# TLE986x register map
File version: 2.5
Registers are 32-bit, read-write, reset 0x0 unless marked. A register's access mark holds for its fields unless they carry their own. Offsets are from the block's base; [hi:lo] are bit positions; {n}, {i} and the like mark numbered series; 'fields as' and 'values as' point back to an identical list.

## ADC2
Base 0x4801C000
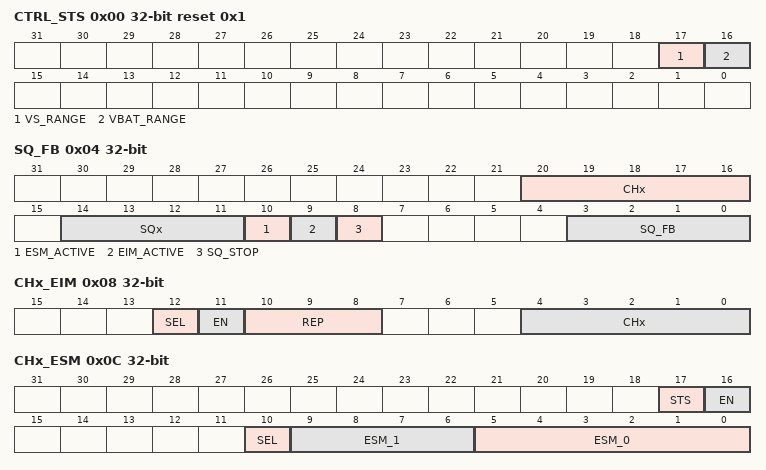
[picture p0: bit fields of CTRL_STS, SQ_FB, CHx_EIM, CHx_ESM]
0x00 CTRL_STS reset 0x1 — ADC2 Control and Status Register
  [17] VS_RANGE — ADC2 Channel 1 Range Selection
    0=Range 1 (Range from 3 to 22 V is selected); 1=Range 2 (Range from 3 to 28 V is selected)
  [16] VBAT_RANGE — ADC2 Channel 0 Range Selection
    values as VS_RANGE
0x04 SQ_FB ro (reset mask 0xFFE080F0) — Sequencer Feedback Register
  [20:16] CHx — Current ADC2 Channel
    {v}=CH{v} (Channel {v} enable) (v=0..6); 29=CH7 (Channel 7 enable); 30=CH8 (Channel 8 enable); 31=CH9 (Channel 9 enable)
  [14:11] SQx — Current Active Sequencer
    {v}=SQ{v} (Sequence {v} enable) (v=0..9)
  [10] ESM_ACTIVE — ADC2 ESM active
    0=not active (ESM not active); 1=active (ESM active)
  [9] EIM_ACTIVE — ADC2 EIM active
    0=not active (EIM not active); 1=active (EIM active)
  [8] SQ_STOP — ADC2 Sequencer Stop Signal for DPP
    0=DPP Running (Postprocessing Sequencer in running mode); 1=DPP Stopped (Postprocessing Sequencer stopped / Software Mode entered)
  [3:0] SQ_FB — Current Sequence that caused software mode
    {v}=SQ{v+1} (Sequence {v+1}) (v=0..9); 10=ESM; 11=CH_MASK (Channel Mask = 0); 12=SUSPEND (Debug Suspend Mode)
0x08 CHx_EIM — Channel Settings Bits for Exceptional Interrupt Measurement
  [12] SEL — Exceptional interrupt measurement (EIM) Trigger Trigger select
    0=CCU6_SEL (ccu6_int triggers EIM); 1=CP_SEL (cp_clk triggers EIM)
  [11] EN — Exceptional interrupt measurement (EIM) Trigger Event enable
    0=DISABLE (start of EIM disabled); 1=ENABLE (start of IEM enabled)
  [10:8] REP — Repeat count for exceptional interrupt measurement (EIM)
    {v}=Measurements (v=0..7)
  [4:0] CHx — Channel set for exceptional interrupt measurement (EIM)
    {v}=CH{v}_EN (Channel {v} enable) (v=0..6); 29=CH7_EN (Channel 7 enable); 30=CH8_EN (Channel 8 enable); 31=CH9_EN (Channel 9 enable)
0x0C CHx_ESM access per field — Channel Settings Bits for Exceptional Sequence Measurement
  [17] STS ro — Exceptional Sequence Measurement is finished
    0=not active (Exceptional Sequence Measurement not done); 1=done (Exceptional Sequence Measurement done)
  [16] EN rw — Enable for Exceptional Sequence Measurement Trigger Event
    0=Disable (start of ESM disabled); 1=Enable (start of ESM enabled)
  [10] SEL rw — Exceptional Sequence Measurement Trigger Select
    0=CCU6_SEL (ccu6_int starts ESM); 1=CP_SEL (cp_clk starts ESM)
  [9:6] ESM_1 rw — Channel Sequence for Exceptional Sequence Measurement (ESM)
    1=CH6_EN (Channel 6 enable); 2=CH7_EN (Channel 7 enable); 4=CH8_EN (Channel 8 enable); 8=CH9_EN (Channel 9 enable)
  [5:0] ESM_0 rw — Channel Sequence for Exceptional Sequence Measurement (ESM)
    1=CH0_EN (Channel 0 enable); 2=CH1_EN (Channel 1 enable); 4=CH2_EN (Channel 2 enable); 8=CH3_EN (Channel 3 enable); 16=CH4_EN (Channel 4 enable); 32=CH5_EN (Channel 5 enable)
0x14 CTRL1 — Measurement Unit Control Register 1
  [5:0] CALIB_EN — Calibration Enable for Channels 0 to 5
    1=CH0_EN (Channel 0 calibration enable); 2=CH1_EN (Channel 1 calibration enable); 4=CH2_EN (Channel 2 calibration enable); 8=CH3_EN (Channel 3 calibration enable); 16=CH4_EN (Channel 4 calibration enable); 32=CH5_EN (Channel 5 calibration enable)
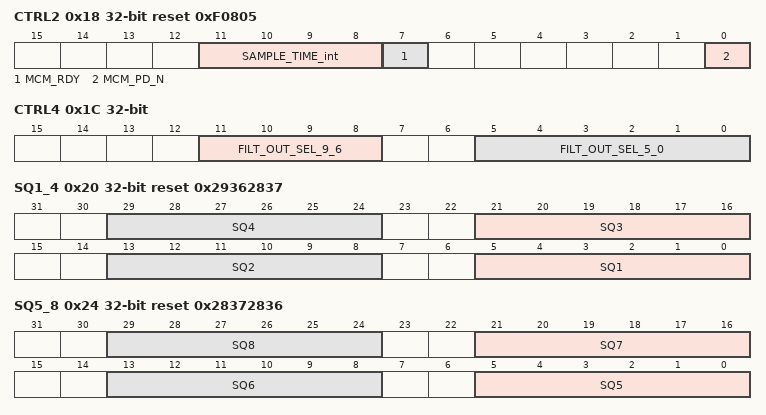
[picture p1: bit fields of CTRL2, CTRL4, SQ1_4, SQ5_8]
0x18 CTRL2 access per field reset 0xF0805 — Measurement Unit Control Register 2
  [11:8] SAMPLE_TIME_int rw — Sample time of ADC2
    0=MICLK4 (4 MI_CLK clock periods); 1=MICLK6 (6 MI_CLK clock periods); 2=MICLK8 (8 MI_CLK clock periods); 3=MICLK10 (10 MI_CLK clock periods); 4=MICLK12 (12 MI_CLK clock periods (default)); 5=MICLK14 (14 MI_CLK clock periods); 6=MICLK16 (16 MI_CLK clock periods); 7=MICLK18 (18 MI_CLK clock periods); 8=MICLK20 (20 MI_CLK clock periods); 9=MICLK22 (22 MI_CLK clock periods); {v}=n.u. (not used) (v=10..15)
  [7] MCM_RDY ro — Ready Signal for MCM after Power On or Reset
    0=MCM Not Ready (Measurement Core Module in startup phase); 1=MCM Ready (Measurement Core Module start-up phase finished)
  [0] MCM_PD_N rw — Power Down Signal for MCM
    0=MCM Disabled (Measurement Core Module Disabled); 1=MCM Enabled (Measurement Core Module Enabled)
0x1C CTRL4 — Measurement Unit Control Register 4
  [11:8] FILT_OUT_SEL_9_6 — Output Filter Selection for Channels 6 to 9
    0=ADC2 Unfiltered Data (can be monitored in the corresponding ADC2_FILT_OUTx Registers.); 1=Channel 6 IIR Data enabled for ADC2_FILT_OUT6 Register; 2=Channel 7 IIR Data enabled for ADC2_FILT_OUT7 Register; 4=Channel 8 IIR Data enabled for ADC2_FILT_OUT8 Register; 8=Channel 9 IIR Data enabled for ADC2_FILT_OUT9 Register; 15=For Channels 9-6 IIR Data is enabled for ADC2_FILT_OUTx Registers
  [5:0] FILT_OUT_SEL_5_0 — Output Filter Selection for Channels 0 to 5
    0=ADC2 Unfiltered D ata can be monitored in the corresponding ADC2_FILT_OUTx Registers; 1=Channel 0 IIR Data enabled for ADC2_FILT_OUT0 Register; 2=Channel 1 IIR Data enabled for ADC2_FILT_OUT1 Register; 4=Channel 2 IIR Data enabled for ADC2_FILT_OUT2 Register; 8=Channel 3 IIR Data enabled for ADC2_FILT_OUT3 Register; 16=Channel 4 IIR Data enabled for ADC2_FILT_OUT4 Register; 32=Channel 5 IIR Data enabled for ADC2_FILT_OUT5 Register; 63=For Channels 5-0 IIR Data is enabled for ADC2_FILT_OUTx Registers
0x20 SQ1_4 reset 0x29362837 — Measurement Channel Enable Bits for Cycle 1-4
  [all] fields
    values as CHx_ESM.ESM_0
  [8n-3:8n-8] SQ{n} (n=1..4) — Sequence {n} channel enable
0x24 SQ5_8 reset 0x28372836 — Measurement Channel Enable Bits for Cycle 5 - 8
  [all] fields
    values as CHx_ESM.ESM_0
  [8n-35:8n-40] SQ{n} (n=5..8) — Sequence {n} channel enable
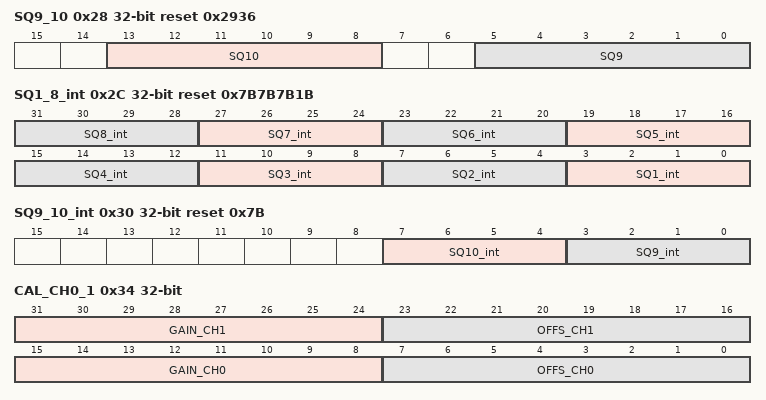
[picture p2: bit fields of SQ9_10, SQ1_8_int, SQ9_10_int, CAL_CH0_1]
0x28 SQ9_10 reset 0x2936 — Measurement Channel Enable Bits for Cycle 9 - 10
  [13:8] SQ10 — Sequence 10 channel enable
    values as CHx_ESM.ESM_0
  [5:0] SQ9 — Sequence 9 channel enable
    values as CHx_ESM.ESM_0
0x2C SQ1_8_int ro reset 0x7B7B7B1B — Measurement Channel Enable Bits for Cycle 1 - 8
  [all] fields
    values as CHx_ESM.ESM_1
  [4n-1:4n-4] SQ{n}_int (n=1..8) — Sequence {n} channel enable
0x30 SQ9_10_int ro reset 0x7B — Measurement Channel Enable Bits for Cycle 9 and 10
  [7:4] SQ10_int — Sequence 10 channel enable
    values as CHx_ESM.ESM_1
  [3:0] SQ9_int — Sequence 9 channel enable
    values as CHx_ESM.ESM_1
0x34 CAL_CH0_1 — Calibration for Channel 0 & 1
  [31:24] GAIN_CH1 — Gain Calibration for channel 1
  [23:16] OFFS_CH1 — Offset Calibration for channel 1
  [15:8] GAIN_CH0 — Gain Calibration for channel 0
  [7:0] OFFS_CH0 — Offset Calibration for channel 0
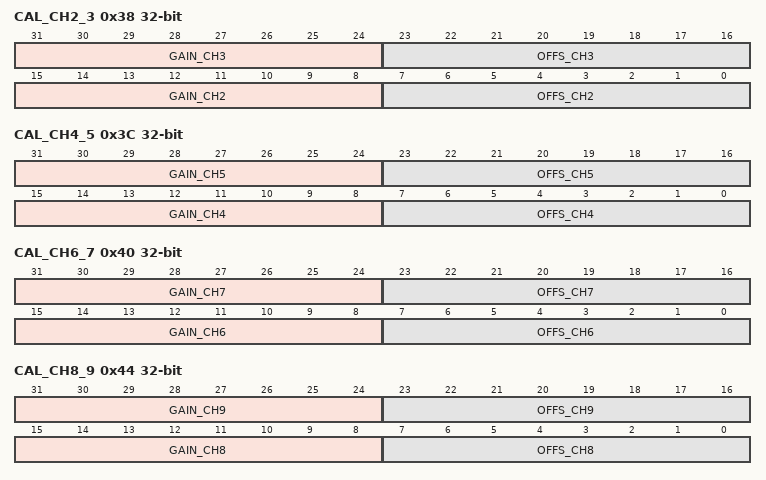
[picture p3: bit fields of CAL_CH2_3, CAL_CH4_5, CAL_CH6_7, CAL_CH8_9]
0x38 CAL_CH2_3 — Calibration for Channel 2 & 3
  [31:24] GAIN_CH3 — Gain Calibration for channel 3
  [23:16] OFFS_CH3 — Offset Calibration for channel 3
  [15:8] GAIN_CH2 — Gain Calibration for channel 2
  [7:0] OFFS_CH2 — Offset Calibration for channel 2
0x3C CAL_CH4_5 — Calibration for Channel 4 & 5
  [31:24] GAIN_CH5 — Gain Calibration for channel 5
  [23:16] OFFS_CH5 — Offset Calibration for channel 5
  [15:8] GAIN_CH4 — Gain Calibration for channel 4
  [7:0] OFFS_CH4 — Offset Calibration for channel 4
0x40 CAL_CH6_7 ro — Calibration for Channel 6 & 7
  [31:24] GAIN_CH7 — Gain Calibration for channel 7
  [23:16] OFFS_CH7 — Offset Calibration for channel 7
  [15:8] GAIN_CH6 — Gain Calibration for channel 6
  [7:0] OFFS_CH6 — Offset Calibration for channel 6
0x44 CAL_CH8_9 ro — Calibration for Channel 8 & 9
  [31:24] GAIN_CH9 — Gain Calibration for channel 9
  [23:16] OFFS_CH9 — Offset Calibration for channel 9
  [15:8] GAIN_CH8 — Gain Calibration for channel 8
  [7:0] OFFS_CH8 — Offset Calibration for channel 8
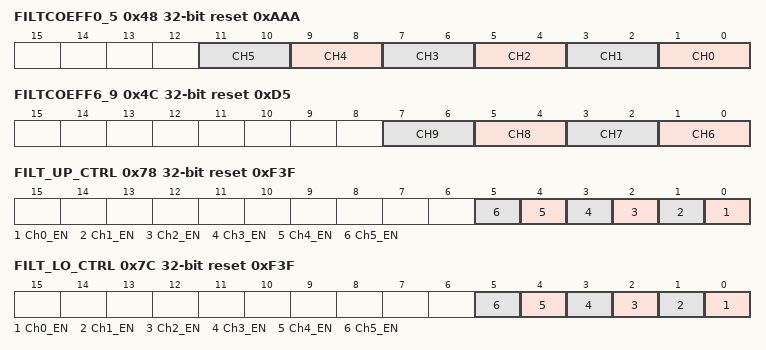
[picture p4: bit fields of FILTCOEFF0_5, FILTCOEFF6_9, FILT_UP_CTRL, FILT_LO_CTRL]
0x48 FILTCOEFF0_5 reset 0xAAA — Filter Coefficients ADC Channel 0-5
  [all] fields
    0=1/2 (weight of current sample); 1=1/4 (weight of current sample); 2=1/8 (weight of current sample); 3=1/16 (weight of current sample)
  [2n+1:2n] CH{n} (n=0..5) — Filter Coefficients ADC channel {n}
0x4C FILTCOEFF6_9 ro reset 0xD5 — Filter Coefficents ADC Channel 6-9
  [all] fields
    values as the fields of FILTCOEFF0_5
  [2n-11:2n-12] CH{n} (n=6..9) — Filter Coefficients ADC channel {n}
{0x50+4i} FILT_OUT{i} ro (reset mask 0xFFFFFC00) (i=0..9) — ADC or Filter Output Channel {i}
  [9:0] OUT_CH{i} — ADC or filter output value channel {i}
0x78 FILT_UP_CTRL reset 0xF3F — Upper Threshold Filter Enable
  [all] fields
    0=disable; 1=enable
  [n] Ch{n}_EN (n=0..5) — Upper threshold IIR filter enable ch {n}
0x7C FILT_LO_CTRL reset 0xF3F — Lower Threshold Filter Enable
  [all] fields
    0=disable; 1=enable
  [n] Ch{n}_EN (n=0..5) — Lower threshold IIR filter enable ch {n}
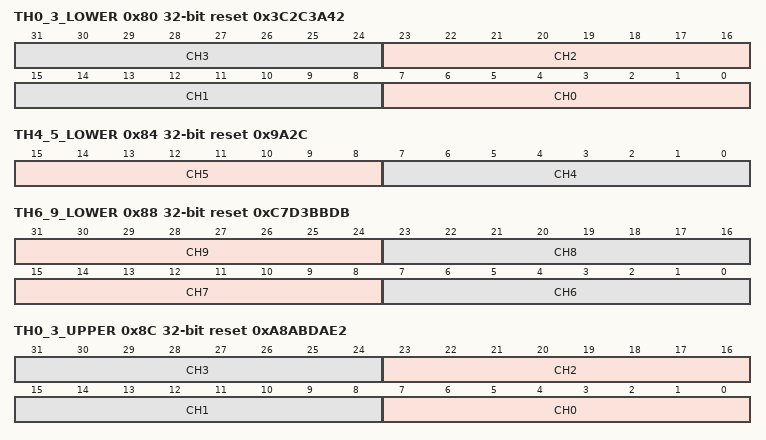
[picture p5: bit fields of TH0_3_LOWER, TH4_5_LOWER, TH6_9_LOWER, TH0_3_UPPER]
0x80 TH0_3_LOWER reset 0x3C2C3A42 — Lower Comparator Trigger Level Channel 0 -3
  [all] fields
    0=Min. threshold value; 255=Max. threshold value
  [8n+7:8n] CH{n} (n=0..3) — Channel {n} lower trigger level
0x84 TH4_5_LOWER reset 0x9A2C — Lower Comparator Trigger Level Channel 4 & 5
  [15:8] CH5 — Channel 5 lower trigger level
    0=Min. threshold value; 255=Max. threshold value
  [7:0] CH4 — Channel 4 lower trigger level
    0=Min. threshold value; 255=Max. threshold value
0x88 TH6_9_LOWER access per field reset 0xC7D3BBDB — Lower Comparator Trigger Level Channel 6 -9
  [all] fields
    0=Min. threshold value; 255=Max. threshold value
  [31:24] CH9 rw — Channel 9 lower trigger level
  [23:16] CH8 rw — Channel 8 lower trigger level
  [15:8] CH7 ro — Channel 7 lower trigger level
  [7:0] CH6 rw — Channel 6 lower trigger level
0x8C TH0_3_UPPER reset 0xA8ABDAE2 — Upper Comparator Trigger Level Channel 0-3
  [all] fields
    0=min. threshold value = 0; 255=max. threshold value = 255
  [8n+7:8n] CH{n} (n=0..3) — Channel {n} upper trigger level
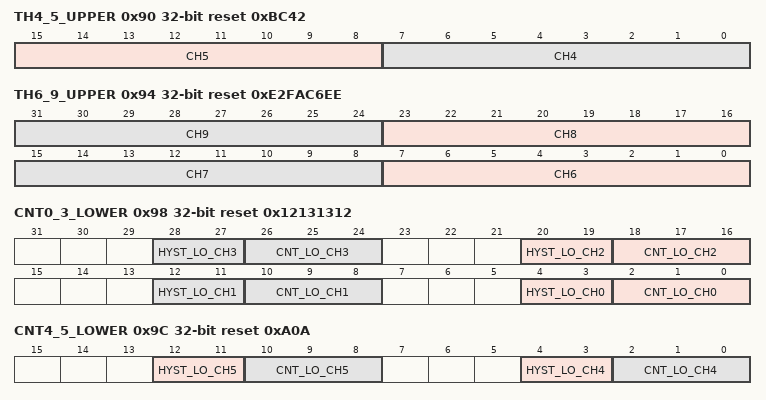
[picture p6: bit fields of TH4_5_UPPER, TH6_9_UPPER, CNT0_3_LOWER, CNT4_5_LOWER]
0x90 TH4_5_UPPER reset 0xBC42 — Upper Comparator Trigger Level Channel 4 -5
  [15:8] CH5 — Channel 5 upper trigger level
    0=min. threshold value = 0; 255=max. threshold value = 255
  [7:0] CH4 — Channel 4 upper trigger level
    0=min. threshold value = 0; 255=max. threshold value = 255
0x94 TH6_9_UPPER ro reset 0xE2FAC6EE — Upper Comparator Trigger Level Channel 6 -9
  [all] fields
    0=min. threshold value = 0; 255=max. threshold value = 255
  [8n-41:8n-48] CH{n} (n=6..9) — Channel {n} upper trigger level
0x98 CNT0_3_LOWER reset 0x12131312 — Lower Counter Trigger Level Channel 0 - 3
  [8n+4:8n+3] HYST_LO_CH{n} (n=0..3) — Channel {n} lower hysteresis
    0=HYSTOFF (hysteresis switched off); 1=HYST4 (hysteresis = 4); 2=HYST8 (hysteresis = 8); 3=HYST16 (hysteresis = 16)
  [8n+2:8n] CNT_LO_CH{n} (n=0..3) — Lower timer trigger threshold channel {n}
    0=1 measurement; 1=2 measurements; 2=4 measurements; 3=8 measurements; 4=16 measurements; 5=32 measurements; 6=64 measurements; 7=128 measurements
0x9C CNT4_5_LOWER reset 0xA0A — Lower Counter Trigger Level Channel 4 & 5
  [12:11] HYST_LO_CH5 — Channel 5 lower hysteresis
    values as CNT0_3_LOWER.HYST_LO_CH0
  [10:8] CNT_LO_CH5 — Lower timer trigger threshold channel 5
    values as CNT0_3_LOWER.CNT_LO_CH0
  [4:3] HYST_LO_CH4 — Channel 4 lower hysteresis
    values as CNT0_3_LOWER.HYST_LO_CH0
  [2:0] CNT_LO_CH4 — Lower timer trigger threshold channel 4
    values as CNT0_3_LOWER.CNT_LO_CH0
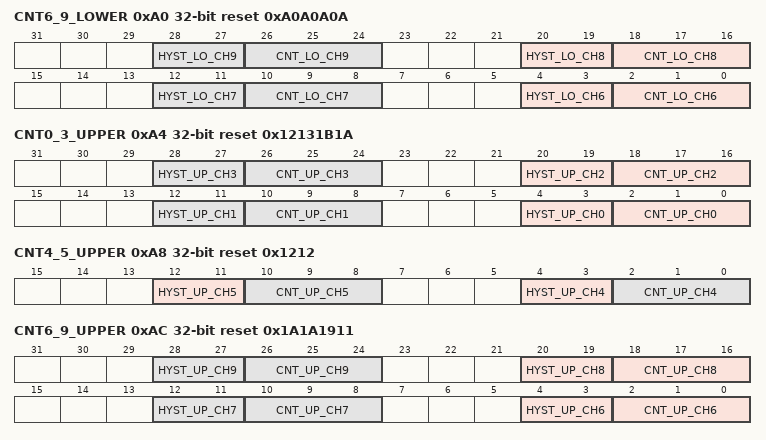
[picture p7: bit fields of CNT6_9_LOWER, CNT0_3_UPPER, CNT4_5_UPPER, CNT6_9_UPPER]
0xA0 CNT6_9_LOWER ro reset 0xA0A0A0A — Lower Counter Trigger Level Channel 6 - 9
  [8n-44:8n-45] HYST_LO_CH{n} (n=6..9) — Channel {n} lower hysteresis
    values as CNT0_3_LOWER.HYST_LO_CH0
  [8n-46:8n-48] CNT_LO_CH{n} (n=6..9) — Lower timer trigger threshold channel {n}
    values as CNT0_3_LOWER.CNT_LO_CH0
0xA4 CNT0_3_UPPER reset 0x12131B1A — Upper Counter Trigger Level Channel 0 - 3
  [8n+4:8n+3] HYST_UP_CH{n} (n=0..3) — Channel {n} upper hysteresis
    values as CNT0_3_LOWER.HYST_LO_CH0
  [8n+2:8n] CNT_UP_CH{n} (n=0..3) — Upper timer trigger threshold channel {n}
    values as CNT0_3_LOWER.CNT_LO_CH0
0xA8 CNT4_5_UPPER reset 0x1212 — Upper Counter Trigger Level Channel 4 & 5
  [12:11] HYST_UP_CH5 — Channel 5 upper hysteresis
    values as CNT0_3_LOWER.HYST_LO_CH0
  [10:8] CNT_UP_CH5 — Upper timer trigger threshold channel 5
    values as CNT0_3_LOWER.CNT_LO_CH0
  [4:3] HYST_UP_CH4 — Channel 4 upper hysteresis
    values as CNT0_3_LOWER.HYST_LO_CH0
  [2:0] CNT_UP_CH4 — Upper timer trigger threshold channel 4
    values as CNT0_3_LOWER.CNT_LO_CH0
0xAC CNT6_9_UPPER ro reset 0x1A1A1911 — Upper Counter Trigger Level Channel 6 -9
  [8n-44:8n-45] HYST_UP_CH{n} (n=6..9) — Channel {n} upper hysteresis
    values as CNT0_3_LOWER.HYST_LO_CH0
  [8n-46:8n-48] CNT_UP_CH{n} (n=6..9) — Upper timer trigger threshold channel {n}
    values as CNT0_3_LOWER.CNT_LO_CH0
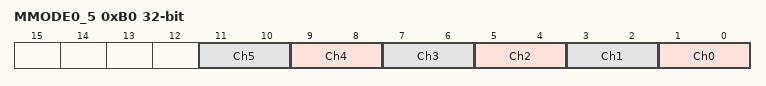
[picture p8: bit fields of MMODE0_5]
0xB0 MMODE0_5 — Overvoltage Measurement Mode of Ch 0-5
  [all] fields
    0=MMODE0 (upper & lower voltage/limit measurement); 1=MMODEUV (undervoltage/-limit measurement); 2=MMODEOV (overvoltage/-limit measurement)
  [2n+1:2n] Ch{n} (n=0..5) — Measurement mode ch {n}
0xBC HV_STS ro — ADC2 HV Status Register
  [1] READY — HVADC Ready bit
    0=Not ready (Module in power down or in init phase); 1=Ready (set automatically 5 ADC clock cycles after module is enabled)
